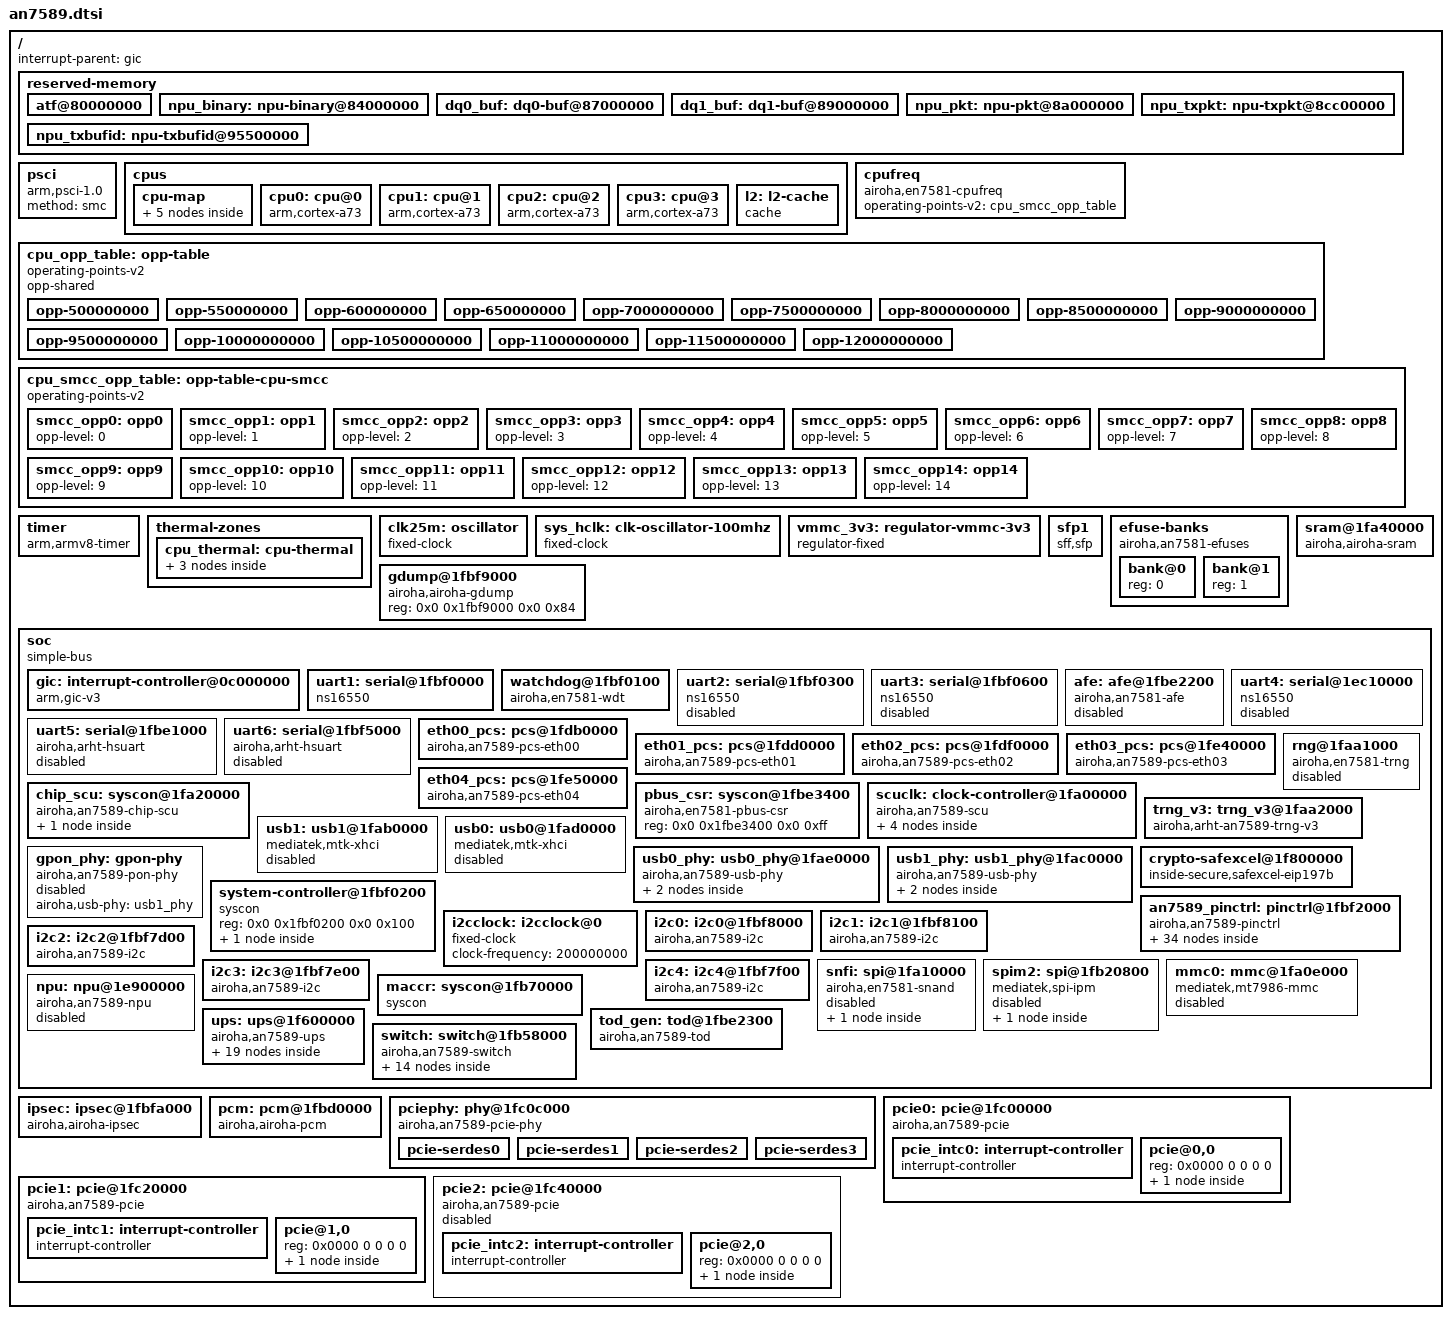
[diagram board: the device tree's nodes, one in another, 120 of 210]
// SPDX-License-Identifier: (GPL-2.0-only OR BSD-2-Clause)

#include <dt-bindings/interrupt-controller/irq.h>
#include <dt-bindings/interrupt-controller/arm-gic.h>
#include <dt-bindings/clock/en7523-clk.h>
#include <dt-bindings/phy/phy.h>
#include <dt-bindings/reset/airoha,en7581-reset.h>
#include <dt-bindings/reset/airoha,an7583-reset.h>
#include <dt-bindings/reset/airoha,an7589-reset.h>
#include <dt-bindings/phy/airoha,an7581-usb-phy.h>
#include <dt-bindings/leds/common.h>
#include <dt-bindings/thermal/thermal.h>

/ {
	interrupt-parent = <&gic>;
	#address-cells = <2>;
	#size-cells = <2>;

	reserved-memory {
		#address-cells = <2>;
		#size-cells = <2>;
		ranges;

		atf@80000000 {
			no-map;
			reg = <0x0 0x80000000 0x0 0x200000>;
		};

		npu_binary: npu-binary@84000000 {
			no-map;
			reg = <0x0 0x84000000 0x0 0xa00000>;
		};
		/*
		ai_npu_freeRTOS: ai-npu-freeRTOS@84a00000{
			no-map;
			reg = <0x0 0x84a00000 0x0 0x800000>;
		};
		ai_npu_input: ai-npu-input@85a00000 {
			no-map;
			reg = <0x0 0x85a00000 0x0 0x20000>;
		};

		ai_npu_model: ai-npu-model@86000000 {
			no-map;
			reg = <0x0 0x86000000 0x0 0x100000>;
		};

		ai_npu_mbox: ai-npu-mbox@86100000 {
			no-map;
			reg = <0x0 0x86100000 0x0 0x10000>;
		};
		*/
		dq0_buf: dq0-buf@87000000 {
			no-map;
			reg = <0x0 0x87000000 0x0 0x2000000>;
		};

		dq1_buf: dq1-buf@89000000 {
			no-map;
			reg = <0x0 0x89000000 0x0 0x1000000>;
		};

		npu_pkt: npu-pkt@8a000000 {
			no-map;
			reg = <0x0 0x8a000000 0x0 0x2c00000>;
		};

		npu_txpkt: npu-txpkt@8cc00000 {
			no-map;
			reg = <0x0 0x8cc00000 0x0 0x8900000>;
		};

		npu_txbufid: npu-txbufid@95500000  {
			no-map;
			reg = <0x0 0x95500000 0x0 0x6800>;
		};
	};

	psci {
		compatible = "arm,psci-1.0";
		method = "smc";
	};

	cpus {
		#address-cells = <1>;
		#size-cells = <0>;

		cpu-map {
			cluster0 {
				core0 {
					cpu = <&cpu0>;
				};

				core1 {
					cpu = <&cpu1>;
				};

				core2 {
					cpu = <&cpu2>;
				};

				core3 {
					cpu = <&cpu3>;
				};
			};
		};

		cpu0: cpu@0 {
			device_type = "cpu";
			compatible = "arm,cortex-a73";
			reg = <0x0>;
			operating-points-v2 = <&cpu_opp_table>;
			enable-method = "psci";
			clocks = <&cpufreq>;
			clock-names = "cpu";
			power-domains = <&cpufreq>;
			power-domain-names = "perf";
			next-level-cache = <&l2>;
			#cooling-cells = <2>;
		};

		cpu1: cpu@1 {
			device_type = "cpu";
			compatible = "arm,cortex-a73";
			reg = <0x1>;
			operating-points-v2 = <&cpu_opp_table>;
			enable-method = "psci";
			clocks = <&cpufreq>;
			clock-names = "cpu";
			power-domains = <&cpufreq>;
			power-domain-names = "perf";
			next-level-cache = <&l2>;
			#cooling-cells = <2>;
		};

		cpu2: cpu@2 {
			device_type = "cpu";
			compatible = "arm,cortex-a73";
			reg = <0x2>;
			operating-points-v2 = <&cpu_opp_table>;
			enable-method = "psci";
			clocks = <&cpufreq>;
			clock-names = "cpu";
			power-domains = <&cpufreq>;
			power-domain-names = "perf";
			next-level-cache = <&l2>;
			#cooling-cells = <2>;
		};

		cpu3: cpu@3 {
			device_type = "cpu";
			compatible = "arm,cortex-a73";
			reg = <0x3>;
			operating-points-v2 = <&cpu_opp_table>;
			enable-method = "psci";
			clocks = <&cpufreq>;
			clock-names = "cpu";
			power-domains = <&cpufreq>;
			power-domain-names = "perf";
			next-level-cache = <&l2>;
			#cooling-cells = <2>;
		};

		l2: l2-cache {
			compatible = "cache";
			cache-size = <0x80000>;
			cache-line-size = <64>;
			cache-level = <2>;
			cache-unified;
		};
	};

	cpufreq: cpufreq {
		compatible = "airoha,en7581-cpufreq";

		operating-points-v2 = <&cpu_smcc_opp_table>;

		#power-domain-cells = <0>;
		#clock-cells = <0>;
	};

	cpu_opp_table: opp-table {
		compatible = "operating-points-v2";
		opp-shared;

		opp-500000000 {
			opp-hz = /bits/ 64 <500000000>;
			required-opps = <&smcc_opp0>;
		};

		opp-550000000 {
			opp-hz = /bits/ 64 <550000000>;
			required-opps = <&smcc_opp1>;
		};

		opp-600000000 {
			opp-hz = /bits/ 64 <600000000>;
			required-opps = <&smcc_opp2>;
		};

		opp-650000000 {
			opp-hz = /bits/ 64 <650000000>;
			required-opps = <&smcc_opp3>;
		};

		opp-7000000000 {
			opp-hz = /bits/ 64 <700000000>;
			required-opps = <&smcc_opp4>;
		};

		opp-7500000000 {
			opp-hz = /bits/ 64 <750000000>;
			required-opps = <&smcc_opp5>;
		};

		opp-8000000000 {
			opp-hz = /bits/ 64 <800000000>;
			required-opps = <&smcc_opp6>;
		};

		opp-8500000000 {
			opp-hz = /bits/ 64 <850000000>;
			required-opps = <&smcc_opp7>;
		};

		opp-9000000000 {
			opp-hz = /bits/ 64 <900000000>;
			required-opps = <&smcc_opp8>;
		};

		opp-9500000000 {
			opp-hz = /bits/ 64 <950000000>;
			required-opps = <&smcc_opp9>;
		};

		opp-10000000000 {
			opp-hz = /bits/ 64 <1000000000>;
			required-opps = <&smcc_opp10>;
		};

		opp-10500000000 {
			opp-hz = /bits/ 64 <1050000000>;
			required-opps = <&smcc_opp11>;
		};

		opp-11000000000 {
			opp-hz = /bits/ 64 <1100000000>;
			required-opps = <&smcc_opp12>;
		};

		opp-11500000000 {
			opp-hz = /bits/ 64 <1150000000>;
			required-opps = <&smcc_opp13>;
		};

		opp-12000000000 {
			opp-hz = /bits/ 64 <1200000000>;
			required-opps = <&smcc_opp14>;
		};
	};

	cpu_smcc_opp_table: opp-table-cpu-smcc {
		compatible = "operating-points-v2";

		smcc_opp0: opp0 {
			opp-level = <0>;
		};

		smcc_opp1: opp1 {
			opp-level = <1>;
		};

		smcc_opp2: opp2 {
			opp-level = <2>;
		};

		smcc_opp3: opp3 {
			opp-level = <3>;
		};

		smcc_opp4: opp4 {
			opp-level = <4>;
		};

		smcc_opp5: opp5 {
			opp-level = <5>;
		};

		smcc_opp6: opp6 {
			opp-level = <6>;
		};

		smcc_opp7: opp7 {
			opp-level = <7>;
		};

		smcc_opp8: opp8 {
			opp-level = <8>;
		};

		smcc_opp9: opp9 {
			opp-level = <9>;
		};

		smcc_opp10: opp10 {
			opp-level = <10>;
		};

		smcc_opp11: opp11 {
			opp-level = <11>;
		};

		smcc_opp12: opp12 {
			opp-level = <12>;
		};

		smcc_opp13: opp13 {
			opp-level = <13>;
		};

		smcc_opp14: opp14 {
			opp-level = <14>;
		};
	};

	timer {
		compatible = "arm,armv8-timer";
		interrupt-parent = <&gic>;
		interrupts = <GIC_PPI 13 IRQ_TYPE_LEVEL_LOW>,
			     <GIC_PPI 14 IRQ_TYPE_LEVEL_LOW>,
			     <GIC_PPI 11 IRQ_TYPE_LEVEL_LOW>,
			     <GIC_PPI 10 IRQ_TYPE_LEVEL_LOW>;
	};

	thermal-zones {
		cpu_thermal: cpu-thermal {
			polling-delay-passive = <1000>;
			polling-delay = <5000>;

			thermal-sensors = <&thermal 0>;

			trips {
				cpu_hot: cpu-hot {
					temperature = <95000>;
					hysteresis = <1000>;
					type = "hot";
				};

				cpu-critical {
					temperature = <120000>;
					hysteresis = <1000>;
					type = "critical";
				};
			};
#if 0
			cooling-maps {
				map0 {
					trip = <&cpu_hot>;
					cooling-device = <&cpu0 THERMAL_NO_LIMIT THERMAL_NO_LIMIT>,
							 <&cpu1 THERMAL_NO_LIMIT THERMAL_NO_LIMIT>,
							 <&cpu2 THERMAL_NO_LIMIT THERMAL_NO_LIMIT>,
							 <&cpu3 THERMAL_NO_LIMIT THERMAL_NO_LIMIT>;
				};
			};
#endif
		};
	};

	clk25m: oscillator {
		compatible = "fixed-clock";
		#clock-cells = <0>;
		clock-frequency = <25000000>;
		clock-output-names = "clkxtal";
	};

	sys_hclk: clk-oscillator-100mhz {
		compatible = "fixed-clock";
		#clock-cells = <0>;
		clock-frequency = <100000000>;
		clock-output-names = "sys_hclk";
	};

	vmmc_3v3: regulator-vmmc-3v3 {
		compatible = "regulator-fixed";
		regulator-name = "vmmc";
		regulator-min-microvolt = <3300000>;
		regulator-max-microvolt = <3300000>;
		regulator-always-on;
	};

	sfp1: sfp1 {
		compatible = "sff,sfp";
	};

	efuse-banks {
		compatible = "airoha,an7581-efuses";
		#address-cells = <1>;
		#size-cells = <0>;

		bank@0 {
			reg = <0>;
		};

		bank@1 {
			reg = <1>;
		};
	};

	gdump@1fbf9000 {
		compatible = "airoha,airoha-gdump";
		reg = <0x0 0x1fbf9000 0x0 0x84>;
	};

	sram@1fa40000 {
		compatible = "airoha,airoha-sram";
		reg = <0x0 0x1fa40000 0x0 0x10000>,		//GDMP SRAM
			  <0x0 0x1f400000 0x0 0x10000>;		//GDMP SRAM2 (for 7589)
	};

	soc {
		compatible = "simple-bus";
		#address-cells = <2>;
		#size-cells = <2>;
		ranges;

		gic: interrupt-controller@0c000000{
			compatible = "arm,gic-v3";
			interrupt-controller;
			#interrupt-cells = <3>;
			#address-cells = <1>;
			#size-cells = <1>;
			reg = <0x0 0x0c000000 0x0 0x40000>,
				  <0x0 0x0c080000 0x0 0x200000>,
				  <0x0 0x0c400000 0x0 0x2000>,
				  <0x0 0x0c410000 0x0 0x1000>,
				  <0x0 0x0c420000 0x0 0x1000>;
			interrupts = <GIC_PPI 9 IRQ_TYPE_LEVEL_LOW>;
		};

		uart1: serial@1fbf0000 {
			compatible = "ns16550";
			reg = <0x0 0x1fbf0000 0x0 0x30>;
			reg-io-width = <4>;
			reg-shift = <2>;
			interrupts = <GIC_SPI 74 IRQ_TYPE_LEVEL_HIGH>;
			clock-frequency = <1843200>;
		};

		watchdog@1fbf0100 {
			compatible = "airoha,en7581-wdt";
			reg = <0x0 0x1fbf0100 0x0 0x38>;

			clocks = <&sys_hclk>;
			clock-names = "bus";
		};

		uart2: serial@1fbf0300 {
			compatible = "ns16550";
			reg = <0x0 0x1fbf0300 0x0 0x30>;
			reg-io-width = <4>;
			reg-shift = <2>;
			interrupts = <GIC_SPI 88 IRQ_TYPE_LEVEL_HIGH>;
			clock-frequency = <1843200>;

			status = "disabled";
		};

		uart3: serial@1fbf0600 {
			compatible = "ns16550";
			reg = <0x0 0x1fbf0600 0x0 0x30>;
			reg-io-width = <4>;
			reg-shift = <2>;
			interrupts = <GIC_SPI 110 IRQ_TYPE_LEVEL_HIGH>;
			clock-frequency = <1843200>;

			status = "disabled";
		};

		afe: afe@1fbe2200 {
			compatible = "airoha,an7581-afe";
			reg = <0x0 0x1fbe2200 0x0 0xfc>,
				<0x0 0x1fbe2f00 0x0 0x14>;
			interrupts = <GIC_SPI 104 IRQ_TYPE_LEVEL_HIGH>;

			resets = <&scuclk AN7589_I2S_RST>;

			status = "disabled";
		};

		uart4: serial@1ec10000 {
			compatible = "ns16550";
			reg = <0x0 0x1ec10000 0x0 0x30>;
			reg-io-width = <4>;
			reg-shift = <2>;
			interrupts = <GIC_SPI 160 IRQ_TYPE_LEVEL_HIGH>;
			clock-frequency = <1843200>;

			status = "disabled";
		};

		uart5: serial@1fbe1000 {
			compatible = "airoha,arht-hsuart";
			reg = <0x0 0x1fbe1000 0x0 0x80>;
			reg-io-width = <4>;
			reg-shift = <2>;
			interrupts = <GIC_SPI 117 IRQ_TYPE_LEVEL_HIGH>;
			clock-frequency = <14745600>;
			port-index = <0>;

			status = "disabled";
		};

		uart6: serial@1fbf5000 {
			compatible = "airoha,arht-hsuart";
			reg = <0x0 0x1fbf5000 0x0 0x80>;
			reg-io-width = <4>;
			reg-shift = <2>;
			interrupts = <GIC_SPI 118 IRQ_TYPE_LEVEL_HIGH>;
			clock-frequency = <14745600>;
			port-index = <1>;

			status = "disabled";
		};

		eth00_pcs: pcs@1fdb0000 {
			compatible = "airoha,an7589-pcs-eth00";
			reg = <0x0 0x1fdb0000 0x0 0x64>,
				  <0x0 0x1fdb1000 0x0 0x64>,
				  <0x0 0x1fdb2000 0x0 0x64>,
				  <0x0 0x1fdb3000 0x0 0x64>,
			      <0x0 0x1fdb0a00 0x0 0x1b0>,
			      <0x0 0x1fdb8000 0x0 0x58c>,
			      <0x0 0x1fdb0c00 0x0 0x3a8>,
			      <0x0 0x1fdb9000 0x0 0x748>,
				  <0x0 0x1fdb1c00 0x0 0x400>,
				  <0x0 0x1fdb2c00 0x0 0x400>,
				  <0x0 0x1fdbc000 0x0 0x250>,
				  <0x0 0x1fda0000 0x0 0x9000>;
			reg-names = "hsgmii_an", "hsgmii_an_p1", "hsgmii_an_p2",
					"hsgmii_an_p3","hsgmii_pcs", "multi_sgmii", "usxgmii",
					"hsgmii_rate_adp", "usxgmii_m_1", "usxgmii_m_2", "qsgmii", "pma";

			// resets = <&scuclk AN7583_XSI_MAC_RST>,
			//	 <&scuclk AN7583_XSI_PHY_RST>;
			// reset-names = "mac", "phy";

			airoha,scu = <&scuclk>;
		};

		eth01_pcs: pcs@1fdd0000 {
			compatible = "airoha,an7589-pcs-eth01";
			reg = <0x0 0x1fdd0000 0x0 0x64>,
				  <0x0 0x1fdd1000 0x0 0x64>,
				  <0x0 0x1fdd2000 0x0 0x64>,
				  <0x0 0x1fdd3000 0x0 0x64>,
			      <0x0 0x1fdd0a00 0x0 0x1b0>,
			      <0x0 0x1fdd8000 0x0 0x58c>,
			      <0x0 0x1fdd0c00 0x0 0x3a8>,
			      <0x0 0x1fdd9000 0x0 0x748>,
				  <0x0 0x1fdd1c00 0x0 0x400>,
				  <0x0 0x1fdd2c00 0x0 0x400>,
				  <0x0 0x1fddc000 0x0 0x250>,
				  <0x0 0x1fdc0000 0x0 0x9000>;
			reg-names = "hsgmii_an", "hsgmii_an_p1","hsgmii_an_p2",
					"hsgmii_an_p3","hsgmii_pcs", "multi_sgmii", "usxgmii",
					"hsgmii_rate_adp", "usxgmii_m_1", "usxgmii_m_2",  "qsgmii", "pma";

			// resets = <&scuclk AN7583_XSI_MAC_RST>,
			//	 <&scuclk AN7583_XSI_PHY_RST>;
			// reset-names = "mac", "phy";

			airoha,scu = <&scuclk>;
		};

		eth02_pcs: pcs@1fdf0000 {
			compatible = "airoha,an7589-pcs-eth02";
			reg = <0x0 0x1fdf0000 0x0 0x414>,
				  <0x0 0x1fdf1000 0x0 0x404>,
				  <0x0 0x1fdf2000 0x0 0x764>,
				  <0x0 0x1fdf3000 0x0 0x23c>,
				  <0x0 0x1fdf4000 0x0 0xc0c>,
				  <0x0 0x1fdf5000 0x0 0x424>,
				  <0x0 0x1fdf6000 0x0 0x90c>,
				  <0x0 0x1fdf7000 0x0 0xc20>,
				  <0x0 0x1fdf8000 0x0 0x314>,
				  <0x0 0x1fdf9000 0x0 0xd8>,
				  <0x0 0x1fde0000 0x0 0x9000>;
			reg-names = "ethl_0", "ethl_1", "ethl_misc",
				    "ethl_com", "ethl_txm", "ethl_rxm", "ethl_txl",
				    "ethl_rxl", "ethl_fifo", "ethl_ra", "pma";

			// resets = <&scuclk AN7583_XSI_MAC_RST>,
			//	 <&scuclk AN7583_XSI_PHY_RST>;
			// reset-names = "mac", "phy";

			airoha,scu = <&scuclk>;
		};

		eth03_pcs: pcs@1fe40000 {
			compatible = "airoha,an7589-pcs-eth03";
			reg = <0x0 0x1fe40000 0x0 0x414>,
				  <0x0 0x1fe41000 0x0 0x404>,
				  <0x0 0x1fe42000 0x0 0x764>,
				  <0x0 0x1fe43000 0x0 0x23c>,
				  <0x0 0x1fe44000 0x0 0xc0c>,
				  <0x0 0x1fe45000 0x0 0x424>,
				  <0x0 0x1fe46000 0x0 0x90c>,
				  <0x0 0x1fe47000 0x0 0xc20>,
				  <0x0 0x1fe48000 0x0 0x314>,
				  <0x0 0x1fe49000 0x0 0xd8>,
				  <0x0 0x1fe30000 0x0 0xf000>;
			reg-names = "ethl_0", "ethl_1", "ethl_misc",
				    "ethl_com", "ethl_txm", "ethl_rxm", "ethl_txl",
				    "ethl_rxl", "ethl_fifo", "ethl_ra", "pma";

			// resets = <&scuclk AN7583_XSI_MAC_RST>,
			// 	 <&scuclk AN7583_XSI_PHY_RST>;
			// reset-names = "mac", "phy";

			airoha,scu = <&scuclk>;
		};

		eth04_pcs: pcs@1fe50000 {
			compatible = "airoha,an7589-pcs-eth04";
			reg = <0x0 0x1fe50000 0x0 0x414>,
				  <0x0 0x1fe51000 0x0 0x404>,
				  <0x0 0x1fe52000 0x0 0x764>,
				  <0x0 0x1fe53000 0x0 0x23c>,
				  <0x0 0x1fe54000 0x0 0xc0c>,
				  <0x0 0x1fe55000 0x0 0x424>,
				  <0x0 0x1fe56000 0x0 0x90c>,
				  <0x0 0x1fe57000 0x0 0xc20>,
				  <0x0 0x1fe58000 0x0 0x314>,
				  <0x0 0x1fe59000 0x0 0xd8>,
				  <0x0 0x1feb0000 0x0 0xf000>;
			reg-names = "ethl_0", "ethl_1", "ethl_misc",
				    "ethl_com", "ethl_txm", "ethl_rxm", "ethl_txl",
				    "ethl_rxl", "ethl_fifo", "ethl_ra", "pma";

			resets = <&scuclk AN7583_XSI_MAC_RST>,
				 <&scuclk AN7583_XSI_PHY_RST>;
			reset-names = "mac", "phy";

			airoha,scu = <&scuclk>;
		};

		chip_scu: syscon@1fa20000 {
			compatible = "airoha,an7589-chip-scu", "simple-mfd", "syscon";
			reg = <0x0 0x1fa20000 0x0 0x410>;
			interrupts = <GIC_SPI 103 IRQ_TYPE_LEVEL_HIGH>;
			thermal: thermal-sensor {
				compatible = "airoha,an7589-thermal";
				#thermal-sensor-cells = <0>;
			};
		};

		pbus_csr: syscon@1fbe3400 {
			compatible = "airoha,en7581-pbus-csr", "syscon";
			reg = <0x0 0x1fbe3400 0x0 0xff>;
		};

		scuclk: clock-controller@1fa00000 {
			compatible = "airoha,an7589-scu", "syscon";
			reg = <0x0 0x1fb00000 0x0 0x9fc>;

			#address-cells = <1>;
			#size-cells = <0>;

			#clock-cells = <1>;
			#reset-cells = <1>;

			airoha,chip-scu = <&chip_scu>;

			mdio_0: mdio-bus@c8 {
				compatible = "airoha,an7583-mdio";
				reg = <0xc8>;

				clocks = <&scuclk AN7583_CLK_MDIO0>;
				resets = <&scuclk AN7589_MDIO0>;
			};

			mdio_1: mdio-bus@cc {
				compatible = "airoha,an7583-mdio";
				reg = <0xcc>;

				clocks = <&scuclk AN7583_CLK_MDIO1>;
				resets = <&scuclk AN7589_MDIO1>;
			};

			mdio_2: mdio-bus@d8 {
				compatible = "airoha,an7583-mdio";
				reg = <0xd8>;

				clocks = <&scuclk AN7589_CLK_MDIO2>;
				resets = <&scuclk AN7589_MDIO2>;
			};

			scu_ssr: system-controller {
				compatible = "airoha,an7581-scu-ssr";
			};
		};
		rng@1faa1000 {
			compatible = "airoha,en7581-trng";
			reg = <0x0 0x1faa1000 0x0 0xc04>;
			interrupts = <GIC_SPI 91 IRQ_TYPE_LEVEL_HIGH>;
			status = "disabled";
		};

		trng_v3: trng_v3@1faa2000 {
			compatible = "airoha,arht-an7589-trng-v3";
			reg = <0x0 0x1faa2000 0x0 0x300>;
			interrupts = <GIC_SPI 203 IRQ_TYPE_LEVEL_HIGH>;
			status = "okay";
		};

		usb1: usb1@1fab0000 {
			compatible = "mediatek,mtk-xhci";
			reg = <0x0 0x1fab0000 0x0 0x3e00>,
				<0x0 0x1fab3e00 0x0 0x100>;
			reg-names = "mac", "ippc";
			interrupts = <GIC_SPI 89 IRQ_TYPE_LEVEL_HIGH>;
			phys = <&usb1_u2 PHY_TYPE_USB2>, <&usb1_u3 PHY_TYPE_USB3>;
			status = "disabled";
		};

		usb0: usb0@1fad0000 {
			compatible = "mediatek,mtk-xhci";
			reg = <0x0 0x1fad0000 0x0 0x3e00>,
				<0x0 0x1fad3e00 0x0 0x100>;
			reg-names = "mac", "ippc";
			interrupts = <GIC_SPI 206 IRQ_TYPE_LEVEL_HIGH>;
			phys = <&usb0_u2 PHY_TYPE_USB2>, <&usb0_u3 PHY_TYPE_USB3>;
			status = "disabled";
		};

		usb0_phy: usb0_phy@1fae0000 {
			compatible = "airoha,an7589-usb-phy";
			reg = <0x0 0x1fae0000 0x0 0x11ff>,
			      <0x0 0x1fedf000 0x0 0xff>,
			      <0x0 0x1fed0000 0x0 0x8ff>,
			      <0x0 0x1feda000 0x0 0x3ff>,
			      <0x0 0x1fbe2100 0x0 0xff>;
			reg-names = "phy", "ana", "pma", "dig", "csr";


			airoha,port-id = <0>;
			airoha,scu-ssr = <&scu_ssr>;

			usb0_u2: usb2-phy {
				reg = <0x0>;
				airoha,usb2-monitor-clk-sel = <AIROHA_USB2_MONCLK_SEL1>;

				#phy-cells = <1>;
			};

			usb0_u3: usb3-phy {
				airoha,scu = <&scuclk>;

				#phy-cells = <1>;
			};
		};

		usb1_phy: usb1_phy@1fac0000 {
			compatible = "airoha,an7589-usb-phy";
			reg = <0x0 0x1fac0000 0x0 0x11ff>,
			      <0x0 0x1fe7f000 0x0 0xff>,
			      <0x0 0x1fe70000 0x0 0x8ff>,
			      <0x0 0x1fe7a000 0x0 0x3ff>,
			      <0x0 0x1fbe2000 0x0 0xff>;
			reg-names = "phy", "ana", "pma", "dig", "csr";


			airoha,port-id = <1>;
			airoha,scu-ssr = <&scu_ssr>;

			usb1_u2: usb2-phy {
				reg = <0x0>;
				airoha,usb2-monitor-clk-sel = <AIROHA_USB2_MONCLK_SEL2>;

				#phy-cells = <1>;
			};

			usb1_u3: usb3-phy {
				airoha,scu = <&scuclk>;

				#phy-cells = <1>;
			};
		};

		gpon_phy: gpon-phy {
			compatible = "airoha,an7589-pon-phy";
			airoha,usb-phy = <&usb1_phy>;
			status = "disabled";
		};

		crypto-safexcel@1f800000 {
			compatible = "inside-secure,safexcel-eip197b",
					"security-ip-197_srv";
			reg = <0x0 0x1f800000 0x0 0x200000>,
				<0x0 0x1f630000 0x0 0x8000>;
			interrupts = <GIC_SPI 135 IRQ_TYPE_LEVEL_HIGH>, //63+72
					<GIC_SPI 75 IRQ_TYPE_LEVEL_HIGH>, //3+72
					<GIC_SPI 209 IRQ_TYPE_LEVEL_HIGH>, //137+72
					<GIC_SPI 267 IRQ_TYPE_LEVEL_HIGH>, //195+72
					<GIC_SPI 274 IRQ_TYPE_LEVEL_HIGH>; //202+72
			interrupt-names = "global","ring0","ring1","ring2","ring3";
			status = "okay";
		};

		system-controller@1fbf0200 {
			compatible = "syscon", "simple-mfd";
			reg = <0x0 0x1fbf0200 0x0 0x100>;
#if 0
			en7581_pinctrl: pinctrl {
				compatible = "airoha,en7581-pinctrl";

				interrupt-parent = <&gic>;
				interrupts = <GIC_SPI 26 IRQ_TYPE_LEVEL_HIGH>;

				gpio-controller;
				#gpio-cells = <2>;

				interrupt-controller;
				#interrupt-cells = <2>;
			};
#endif
			an7589_pwm: pwm {
				compatible = "airoha,an7589-pwm";

				#pwm-cells = <3>;
			};
		};


		/*
		 * GPIO and Pinctrl Controller
		 *
		 * AN7589 uses two separate register regions:
		 * 1. GPIO control base @ 0x1FBF2000 - DIR, DOUT, DIN, INT, PULL, DRV
		 *    (Source: AN7589_GPIO_CODA_GPIO_internal.docx)
		 * 2. IOMUX base @ 0x1FA30000 - MODE registers for pin multiplexing
		 *    (Source: acd2coda_default_gpio_reg_internal.docx)
		 */
		an7589_pinctrl: pinctrl@1fbf2000 {
			compatible = "airoha,an7589-pinctrl";

			/* Two register regions */
			reg = <0x0 0x1fbf0200 0x0 0x100>,  /* GPIO control base */
			      <0x0 0x1fa30000 0x0 0x34>;  /* IOMUX base */
			reg-names = "base", "iomux";

			gpio-controller;
			#gpio-cells = <2>;

			interrupt-controller;
			#interrupt-cells = <2>;
			interrupts = <GIC_SPI 82 IRQ_TYPE_LEVEL_HIGH>;

			i2c0_pins: i2c0-pins {
				mux {
					function = "i2c0";
					groups = "i2c0_grp";
				};
			};

			i2c3_pins: i2c3-pins {
				mux {
					function = "i2c3";
					groups = "i2c3_grp";
				};
			};

			mmc_pins: mmc-pins {
				mux {
					function = "emmc";
					groups = "emmc_grp";
				};
			};

			uart2_pins: uart2-pins {
				mux {
					function = "uart2";
					groups = "uart2_grp";
				};
			};

			uart3_pins: uart3-pins {
				mux {
					function = "uart3";
					groups = "uart3_grp";
				};
			};

			uart4_pins: uart4-pins {
				mux {
					function = "uart4";
					groups = "uart4_grp";
				};
			};

			uart5_pins: uart5-pins {
				mux {
					function = "uart5";
					groups = "uart5_grp";
				};
			};

			uart6_pins: uart6-pins {
				mux {
					function = "uart6";
					groups = "uart6_grp";
				};
			};

			i2s_pins: i2s-pins {
				mux {
					function = "i2s";
					groups = "i2s_grp";
				};
			};

			pcm1_pins: pcm1-pins {
				mux {
					function = "pcm1";
					groups = "pcm1_grp";
				};
			};

			pon1_default_pins: pon1_default_pins {
				mux {
					function = "pon1";
					groups = "pon1_default_grp";
				};
			};

			pon1_working_pins: pon1_working_pins {
				mux {
					function = "pon1";
					groups = "pon1_working_grp";
				};
			};

			pon1_reset_pins: pon1_reset_pins {
				mux {
					function = "pon1";
					groups = "pon1_reset_grp";
				};
			};

			pon2_default_pins: pon2_default_pins {
				mux {
					function = "pon2";
					groups = "pon2_default_grp";
				};
			};

			pon2_working_pins: pon2_working_pins {
				mux {
					function = "pon2";
					groups = "pon2_working_grp";
				};
			};

			pon2_reset_pins: pon2_reset_pins {
				mux {
					function = "pon2";
					groups = "pon2_reset_grp";
				};
			};

			ext_spi2_full_pins: ext-spi2-full-pins {
				mux {
					function = "ext_spi2";
					groups = "ext_spi2_full_grp";
				};
			};
		};

#if 0
		spi_ctrl: spi_controller@1fa10000 {
			compatible = "econet,ecnt-spi_ctrl";
			reg = <0x0 0x1fa10000 0x0 0x140>,		//SPI Controller Base
				  <0x0 0x00000000 0x0 0x1000>;		//SPI Controller auto read interrupt test
			interrupts = <GIC_SPI 51 IRQ_TYPE_LEVEL_HIGH>;
		};

		spi_spi2nfi: spi_spi2nfi@1fa11000 {
			compatible = "econet,ecnt-spi2nfi";
			reg = <0x0 0x1fa11000 0x0 0x160>;	//NFI2SPI
		};

		spi_ecc: spi_ecc@1fa12000 {
			compatible = "econet,ecnt-spi_ecc";
			reg = <0x0 0x1fa12000 0x0 0x150>;	//NFI ECC
		};

		nand_flash: nand@1fa10000 {
			compatible = "econet,ecnt-nand";
			spi-controller = <&spi_ctrl>;
			spi2nfi = <&spi_spi2nfi>;
			spi-ecc = <&spi_ecc>;
		};
#endif
		i2cclock: i2cclock@0 {
			#clock-cells = <0>;
			compatible = "fixed-clock";

			/* 160 MHz for FPGA, 200 MHz for ASIC*/
			clock-frequency = <200000000>;
		};

		i2c0: i2c0@1fbf8000 {
			compatible = "airoha,an7589-i2c";
			reg = <0x0 0x1fbf8000 0x0 0x100>;

			clocks = <&i2cclock>;

			/* 100 kHz */
			clock-frequency = <100000>;
			#address-cells = <1>;
			#size-cells = <0>;

			status = "okay";
		};

		i2c1: i2c1@1fbf8100 {
			compatible = "airoha,an7589-i2c";
			reg = <0x0 0x1fbf8100 0x0 0x100>;

			clocks = <&i2cclock>;

			/* 100 kHz */
			clock-frequency = <100000>;
			#address-cells = <1>;
			#size-cells = <0>;

			status = "okay";
		};

		i2c2: i2c2@1fbf7d00 {
			compatible = "airoha,an7589-i2c";
			reg = <0x0 0x1fbf7d00 0x0 0x100>;

			clocks = <&i2cclock>;

			/* 100 kHz */
			clock-frequency = <100000>;
			#address-cells = <1>;
			#size-cells = <0>;

			status = "okay";
		};

		i2c3: i2c3@1fbf7e00 {
			compatible = "airoha,an7589-i2c";
			reg = <0x0 0x1fbf7e00 0x0 0x100>;

			clocks = <&i2cclock>;

			/* 100 kHz */
			clock-frequency = <100000>;
			#address-cells = <1>;
			#size-cells = <0>;

			status = "okay";
		};

		i2c4: i2c4@1fbf7f00 {
			compatible = "airoha,an7589-i2c";
			reg = <0x0 0x1fbf7f00 0x0 0x100>;

			clocks = <&i2cclock>;

			/* 100 kHz */
			clock-frequency = <100000>;
			#address-cells = <1>;
			#size-cells = <0>;

			status = "okay";
		};

		snfi: spi@1fa10000 {
			compatible = "airoha,en7581-snand";
			reg = <0x0 0x1fa10000 0x0 0x140>,
			      <0x0 0x1fa11000 0x0 0x600>;

			clocks = <&scuclk EN7523_CLK_SPI>;
			clock-names = "spi";

			#address-cells = <1>;
			#size-cells = <0>;

			status = "disabled";

			spi_nand: nand@0 {
				compatible = "spi-nand";
				reg = <0>;
				spi-max-frequency = <50000000>;
				spi-tx-bus-width = <1>;
				spi-rx-bus-width = <2>;
			};
		};

		/* Non-boot SPI-NOR connected to SPIM2 (GPIO27/28/30-33). */
		spim2: spi@1fb20800 {
			compatible = "mediatek,spi-ipm";
			reg = <0 0x1fb20800 0 0x1000>;
			interrupts = <GIC_SPI 203 IRQ_TYPE_LEVEL_HIGH>;
			pinctrl-names = "default";
			pinctrl-0 = <&ext_spi2_full_pins>;
			mediatek,pad-select = <0>;
			clocks = <&scuclk CLK_TOP_CB_M_D2>,
				 <&scuclk CLK_TOP_SPI2_SEL>,
				 <&scuclk CLK_INFRA_104M_SPI2>,
				 <&scuclk CLK_INFRA_66M_SPI2_HCK>;
			clock-names = "parent-clk", "sel-clk", "spi-clk", "hclk";
			/* Select the 200 MHz SPIM2 source; IPM divides it to 50 MHz. */
			assigned-clocks = <&scuclk CLK_INFRA_104M_SPI2>;
			assigned-clock-rates = <200000000>;
			#address-cells = <1>;
			#size-cells = <0>;
			status = "disabled";

			spim2_nor: flash@0 {
				compatible = "jedec,spi-nor";
				reg = <0>;
				spi-max-frequency = <50000000>;
				/* AN7589 IPM input sampling delay for the external NOR. */
				mediatek,tick-delay = <3>;
				/* Validate Dual I/O at the established 50 MHz clock rate. */
				spi-tx-bus-width = <2>;
				spi-rx-bus-width = <2>;

				/*
				 * TODO: Quad I/O requires board support for NOR IO2/IO3.
				 * Do not enable it on the current hardware.
				 * spi-tx-bus-width = <4>;
				 * spi-rx-bus-width = <4>;
				 */
			};
		};

		mmc0: mmc@1fa0e000 {
			compatible = "mediatek,mt7986-mmc";
			reg = <0x0 0x1fa0e000 0x0 0x1000>,
			      <0x0 0x1fa0c000 0x0 0x60>;
			interrupts = <GIC_SPI 226 IRQ_TYPE_LEVEL_HIGH>;	// 226 = 154 + 72
			clocks = <&scuclk EN7581_CLK_EMMC>, <&clk25m>;
			clock-names = "source", "hclk";
			bus-width = <8>;
			max-frequency = <200000000>;
			vmmc-supply = <&vmmc_3v3>;
			disable-wp;
			cap-mmc-highspeed;
			mmc-hs200-1_8v;
			mmc-hs400-1_8v;
			mmc-hs400-enhanced-strobe;
			hs400-ds-delay = <0x14014>;
			non-removable;
			no-sd;
			no-sdio;

			status = "disabled";
		};

		npu: npu@1e900000 {
			compatible = "airoha,an7589-npu";
			reg = <0x0 0x1e900000 0x0 0x317000>, //NEQ reg 0x1ec1_6800 - 0x1ec1_6FFF
				<0x0 0x1e800000 0x0 0x60000>,
				<0x0 0x70200000 0x0 0x88000>,
				<0x0 0x70300000 0x0 0x48000>;
			reg-names = "npuRegs", "shared_SRAM", "cluster0_SPAD", "cluster1_SPAD";
			interrupts = <GIC_SPI 181 IRQ_TYPE_LEVEL_HIGH>, 	//mbox2host irq
				<GIC_SPI 190 IRQ_TYPE_LEVEL_HIGH>,	//npu timer0 wdog intr
				<GIC_SPI 191 IRQ_TYPE_LEVEL_HIGH>,	//npu timer1 wdog intr
				<GIC_SPI 192 IRQ_TYPE_LEVEL_HIGH>,	//npu timer2 wdog intr
				<GIC_SPI 193 IRQ_TYPE_LEVEL_HIGH>,	//npu timer3 wdog intr
				<GIC_SPI 165 IRQ_TYPE_LEVEL_HIGH>,	//npu timer4 wdog intr
				<GIC_SPI 166 IRQ_TYPE_LEVEL_HIGH>,	//npu timer5 wdog intr
				<GIC_SPI 167 IRQ_TYPE_LEVEL_HIGH>,	//npu timer6 wdog intr
				<GIC_SPI 168 IRQ_TYPE_LEVEL_HIGH>,	//npu timer7 wdog intr
				<GIC_SPI 174 IRQ_TYPE_LEVEL_HIGH>,
				<GIC_SPI 175 IRQ_TYPE_LEVEL_HIGH>,
				<GIC_SPI 176 IRQ_TYPE_LEVEL_HIGH>,
				<GIC_SPI 177 IRQ_TYPE_LEVEL_HIGH>,
				<GIC_SPI 178 IRQ_TYPE_LEVEL_HIGH>,
				<GIC_SPI 179 IRQ_TYPE_LEVEL_HIGH>;
			memory-region = <&npu_binary>, <&npu_pkt>, <&npu_txpkt>,
					<&npu_txbufid>;
			memory-region-names = "binary", "pkt", "tx-pkt",
					      "tx-bufid";
			status = "disabled";
		};

		maccr: syscon@1fb70000 {
			compatible = "syscon";
			reg = <0 0x1fb70000 0 0x4700>,
			<0 0x1fb80000 0 0x4700>,
			<0 0x1fb90000 0 0x4100>,
			<0 0x1fba0000 0 0x4100>,
			<0 0x1fbb0000 0 0x4100>;
		};

		tod_gen: tod@1fbe2300 {
			compatible = "airoha,an7589-tod";
			reg = <0x0 0x1fbe2300 0x0 0xD0>;
			interrupts = <GIC_SPI 134 IRQ_TYPE_LEVEL_HIGH>; // TOD GEN INT 62+72
		};

		ups: ups@1f600000 {
			compatible = "airoha,an7589-ups";
			reg = <0x0 0x1f600000 0x0 0x10000>,	//DQ
				  <0x0 0x1f610000 0x0 0x4000>,	//PP
				  <0x0 0x1f614000 0x0 0x1000>,	//PDMA0
				  <0x0 0x1f615000 0x0 0x1000>,	//PDMA1
				  <0x0 0x1f616000 0x0 0x200>,	//PM
				  <0x0 0x1f616200 0x0 0x200>,	//TCE
				  <0x0 0x1f620000 0x0 0x20000>,	//TM
				  <0x0 0x1fa2ff38 0x0 0x4>;		//FPGA_STATUS
			reg-names = "dq","pp","pdma0","pdma1","pm","tce","tm","status";
			reset-names = "pdma0";
			interrupts = <GIC_SPI 93 IRQ_TYPE_LEVEL_HIGH>, // PDMA0 INT1 21+72
						   <GIC_SPI 111 IRQ_TYPE_LEVEL_HIGH>, // PDMA0 INT2 39+72
						   <GIC_SPI 112 IRQ_TYPE_LEVEL_HIGH>, // PDMA0 INT3 40+72
						   <GIC_SPI 113 IRQ_TYPE_LEVEL_HIGH>, // PDMA0 INT4 41+72
						   <GIC_SPI 301 IRQ_TYPE_LEVEL_HIGH>, // serdes00 ptp INT 229+72
						   <GIC_SPI 306 IRQ_TYPE_LEVEL_HIGH>, // serdes01 ptp INT 234+72
						   <GIC_SPI 311 IRQ_TYPE_LEVEL_HIGH>, // serdes02 ptp INT 239+72
						   <GIC_SPI 293 IRQ_TYPE_LEVEL_HIGH>, // serdes03 ptp INT 221+72
						   <GIC_SPI 282 IRQ_TYPE_LEVEL_HIGH>; // serdes04 ptp INT 210+72
			airoha,maccr = <&maccr>;
			memory-region = <&dq0_buf>, <&dq1_buf>;
			memory-region-names = "dq0_buf", "dq1_buf";

			port0: ethernet@0 {
				compatible = "airoha,eth-mac";
				reg = <0>;
				phy-mode = "internal";
				status = "okay";
				pcs = <&eth00_pcs>;

				fixed-link {
					speed = <10000>;
					full-duplex;
					pause;
				};
			};

			port1: ethernet@1 {
				compatible = "airoha,eth-mac";
				reg = <1>;
				phy-mode = "usxgmii";
				status = "okay";
				pcs = <&eth01_pcs>;


			};

			port2: ethernet@2 {
				compatible = "airoha,eth-mac";
				reg = <2>;
				phy-mode = "usxgmii";
				status = "okay";
				pcs = <&eth02_pcs>;


			};

			port3: ethernet@3 {
				compatible = "airoha,eth-mac";
				reg = <3>;
				phy-mode = "usxgmii";
				status = "okay";
				pcs = <&eth03_pcs>;

			};

			port4: ethernet@4 {
				compatible = "airoha,eth-mac";
				reg = <4>;
				phy-mode = "usxgmii";
				status = "okay";
				pcs = <&eth04_pcs>;


			};

			/* reg is keep with switch@1fb58000 subnode ports.*/
			/* type: 0(unknow), 1(cpu), 2(phy), 3(xsi). */
			eth_ports {
				xsi_port0: port@0 {
					label = "serdes_00";
					reg = <0>;
					type = <3>;
					serdes = <0>;
					index = <0>;
					dma_src_port = <0x0>;
					status = "disabled";
				};
				xsi_port1: port@1 {
					label = "serdes_00";
					reg = <1>;
					type = <3>;
					serdes = <0>;
					index = <0>;
					dma_src_port = <0x1>;
					status = "disabled";
				};
				xsi_port2: port@2 {
					label = "serdes_00";
					reg = <2>;
					type = <3>;
					serdes = <0>;
					index = <0>;
					dma_src_port = <0x2>;
					status = "disabled";
				};
				xsi_port3: port@3 {
					label = "serdes_00";
					reg = <3>;
					type = <3>;
					serdes = <0>;
					index = <0>;
					dma_src_port = <0x3>;
					status = "disabled";
				};
				xsi_port4: port@4 {
					label = "serdes_01";
					reg = <4>;
					type = <3>;
					serdes = <1>;
					index = <0>;
					dma_src_port = <0x4>;
					status = "disabled";
				};
				xsi_port5: port@5 {
					label = "serdes_01";
					reg = <5>;
					type = <3>;
					serdes = <1>;
					index = <0>;
					dma_src_port = <0x5>;
					status = "disabled";
				};
				xsi_port6: port@6 {
					label = "serdes_01";
					reg = <6>;
					type = <3>;
					serdes = <1>;
					index = <0>;
					dma_src_port = <0x6>;
					status = "disabled";
				};
				xsi_port7: port@7 {
					label = "serdes_01";
					reg = <7>;
					type = <3>;
					serdes = <1>;
					index = <0>;
					dma_src_port = <0x7>;
					status = "disabled";
				};
				xsi_port8: port@8 {
					label = "serdes_02";
					reg = <8>;
					type = <3>;
					serdes = <1>;
					index = <0>;
					dma_src_port = <0x8>;
					status = "disabled";
				};
				xsi_port9: port@9 {
					label = "serdes_03";
					reg = <9>;
					type = <3>;
					serdes = <1>;
					index = <0>;
					dma_src_port = <0x9>;
					status = "disabled";
				};
				xsi_port10: port@10 {
					label = "serdes_04";
					reg = <10>;
					type = <3>;
					serdes = <1>;
					index = <0>;
					dma_src_port = <0xa>;
					status = "disabled";
				};

				cpu_port: port@12 {
					reg = <12>;
					type = <1>;
					index = <0>;
					dma_src_port = <0xc>;
				};


			};
		};
		switch: switch@1fb58000 {
			compatible = "airoha,an7589-switch";
			airoha,maccr = <&maccr>;
			resets = <&scuclk EN7581_GSW_RST>;

			interrupt-controller;
			#interrupt-cells = <1>;
			interrupt-parent = <&gic>;
			interrupts = <GIC_SPI 265 IRQ_TYPE_LEVEL_HIGH>;

			status = "okay";

			#address-cells = <1>;
			#size-cells = <1>;

			ports {
				#address-cells = <1>;
				#size-cells = <0>;

				an7589_port1: port@0 {
					reg = <0>;
					label = "lan1";
					phy-mode = "10g-qxgmii";
					sfp = <&sfp1>;
					port-handle = <&xsi_port0>;
					managed = "in-band-status";
					status = "disabled";
				};
				an7589_port2: port@1 {
					reg = <1>;
					label = "lan2";
					phy-mode = "10g-qxgmii";
					port-handle = <&xsi_port1>;
					managed = "in-band-status";
					status = "disabled";
				};
				an7589_port3: port@2 {
					reg = <2>;
					label = "lan3";
					phy-mode = "10g-qxgmii";
					port-handle = <&xsi_port2>;
					managed = "in-band-status";
					status = "disabled";
				};
				an7589_port4: port@3 {
					reg = <3>;
					label = "lan4";
					phy-mode = "10g-qxgmii";
					port-handle = <&xsi_port3>;
					managed = "in-band-status";
					status = "disabled";
				};
				an7589_port5: port@4 {
					reg = <4>;
					label = "lan5";
					phy-mode = "usxgmii";
					sfp = <&sfp1>;
					port-handle = <&xsi_port4>;
					managed = "in-band-status";
					status = "disabled";
				};
				an7589_port6: port@5 {
					reg = <5>;
					label = "lan6";
					phy-mode = "10g-qxgmii";
					port-handle = <&xsi_port5>;
					managed = "in-band-status";
					status = "disabled";
				};
				an7589_port7: port@6 {
					reg = <6>;
					label = "lan7";
					phy-mode = "10g-qxgmii";
					port-handle = <&xsi_port6>;
					managed = "in-band-status";
					status = "disabled";
				};
				an7589_port8: port@7 {
					reg = <7>;
					label = "lan8";
					phy-mode = "10g-qxgmii";
					port-handle = <&xsi_port7>;
					managed = "in-band-status";
					status = "disabled";
				};
				an7589_port9: port@8 {
					reg = <8>;
					label = "lan9";
					phy-mode = "usxgmii";
					sfp = <&sfp1>;
					port-handle = <&xsi_port8>;
					managed = "in-band-status";
					status = "disabled";
				};
				an7589_port10: port@9 {
					reg = <9>;
					label = "lan10";
					phy-mode = "usxgmii";
					sfp = <&sfp1>;
					port-handle = <&xsi_port9>;
					managed = "in-band-status";
					status = "disabled";
				};
				an7589_port11: port@10 {
					reg = <10>;
					label = "wan1";
					phy-mode = "usxgmii";
					sfp = <&sfp1>;
					port-handle = <&xsi_port10>;
					managed = "in-band-status";
					status = "disabled";
				};

				port@12 {
					reg = <12>;
					label = "cpu";
					ethernet = <&port0>;
					phy-mode = "internal";

					fixed-link {
						speed = <10000>;
						full-duplex;
						pause;
					};
				};
			};
		};
	};

	ipsec: ipsec@1fbfa000 {
		compatible = "airoha,airoha-ipsec";
		reg = <0x0 0x1fbfa000 0x0 0x268>;
		interrupts = <GIC_SPI 92 IRQ_TYPE_LEVEL_HIGH>; // IPSEC_INTR 20+72
	};

	pcm: pcm@1fbd0000 {
		compatible = "airoha,airoha-pcm";
		reg = <0x0 0x1fbd0000 0x0 0x4fff>;
		interrupts = <GIC_SPI 83 IRQ_TYPE_LEVEL_HIGH>;
	};

#if 1
		pciephy: phy@1fc0c000 {
			compatible = "airoha,an7589-pcie-phy";
			reg = <0x0 0x1fc0c000 0x0 0x800>,
				<0x0 0x1fc2c000 0x0 0x800>,
				<0x0 0x1fc10000 0x0 0xf00>,
				<0x0 0x1fc30000 0x0 0xf00>,
				<0x0 0x1fc50000 0x0 0xf00>;

			reg-names = "phyA-0", "phyA-1", "phyD-0", "phyD-1", "phyD-2";

			#phy-cells = <1>;

			pcie-serdes0{
				phy-index = <0>;
				lane-num = <2>;
			};
			pcie-serdes1{
				phy-index = <1>;
				lane-num = <2>;
			};
			pcie-serdes2{
				phy-index = <2>;
				lane-num = <1>;
			};
			pcie-serdes3{
				phy-index = <3>;
				lane-num = <1>;
			};
		};
#endif

#if 1
pcie0: pcie@1fc00000 {
			compatible = "airoha,an7589-pcie";
			device_type = "pci";
		linux,pci-domain = <0>;
			#address-cells = <3>;
			#size-cells = <2>;

			reg = <0x0 0x1fc00000 0x0 0x1670>;
			reg-names = "pcie-mac";

		phys = <&pciephy 0>,<&pciephy 1>;
		phy-names = "pcie-phy0";

			ranges = <0x02000000 0 0x20000000 0x0 0x20000000  0 0x4000000>;

		resets = <&scuclk AN7589_PCIE0_RST>,
				 <&scuclk AN7589_PCIE1_RST>,
				 <&scuclk AN7589_PCIE2_RST>;
		reset-names = "phy-lane0", "phy-lane1", "phy-lane2";

		mediatek,pbus-csr = <&pbus_csr 0x0 0x4>;

			interrupts = <GIC_SPI 95 IRQ_TYPE_LEVEL_HIGH>;
			bus-range = <0x00 0xff>;
			#interrupt-cells = <1>;
			interrupt-map-mask = <0 0 0 7>;
			interrupt-map = <0 0 0 1 &pcie_intc0 0>,
					<0 0 0 2 &pcie_intc0 1>,
					<0 0 0 3 &pcie_intc0 2>,
					<0 0 0 4 &pcie_intc0 3>;

			wifi-reset-gpios = <&an7589_pinctrl 70 GPIO_ACTIVE_LOW>;
			wifi-reset-msleep = <100>;
			wifi-deassert-msleep = <500>;

			status = "okay";

			pcie_intc0: interrupt-controller {
				interrupt-controller;
				#address-cells = <0>;
				#interrupt-cells = <1>;
			};

			pcie@0,0 {
				reg = <0x0000 0 0 0 0>;
				wifi@0,0 {
					reg = <0x0000 0 0 0 0>;
					airoha,npu = <&npu>;
				};
			};
		};
#endif

#if 1
pcie1: pcie@1fc20000 {
			compatible = "airoha,an7589-pcie";
			device_type = "pci";
		linux,pci-domain = <1>;
			#address-cells = <3>;
			#size-cells = <2>;

			reg = <0x0 0x1fc20000 0x0 0x1670>;
			reg-names = "pcie-mac";

		phys = <&pciephy 2>;
		phy-names = "pcie-phy1";

			ranges = <0x02000000 0 0x30000000 0x0 0x30000000  0 0x4000000>;

		resets = <&scuclk AN7589_PCIE0_RST>,
				 <&scuclk AN7589_PCIE1_RST>,
				 <&scuclk AN7589_PCIE2_RST>;
		reset-names = "phy-lane0", "phy-lane1", "phy-lane2";

		mediatek,pbus-csr = <&pbus_csr 0x8 0xc>;

			interrupts = <GIC_SPI 96 IRQ_TYPE_LEVEL_HIGH>;
			bus-range = <0x00 0xff>;
			#interrupt-cells = <1>;
			interrupt-map-mask = <0 0 0 7>;
			interrupt-map = <0 0 0 1 &pcie_intc1 0>,
					<0 0 0 2 &pcie_intc1 1>,
					<0 0 0 3 &pcie_intc1 2>,
					<0 0 0 4 &pcie_intc1 3>;

			status = "okay";

			pcie_intc1: interrupt-controller {
				interrupt-controller;
				#address-cells = <0>;
				#interrupt-cells = <1>;
			};

			pcie@1,0 {
				reg = <0x0000 0 0 0 0>;
				wifi@1,0 {
					reg = <0x0000 0 0 0 0>;
					airoha,npu = <&npu>;
				};
			};
		};
#endif

#if 1
pcie2: pcie@1fc40000 {
			compatible = "airoha,an7589-pcie";
			device_type = "pci";
		linux,pci-domain = <2>;
			#address-cells = <3>;
			#size-cells = <2>;

			reg = <0x0 0x1fc40000 0x0 0x1670>;
			reg-names = "pcie-mac";

		phys = <&pciephy 3>;
		phy-names = "pcie-phy2";

			ranges = <0x02000000 0 0x40000000 0x0 0x40000000  0 0x4000000>;

		resets = <&scuclk AN7589_PCIE0_RST>,
				 <&scuclk AN7589_PCIE1_RST>,
				 <&scuclk AN7589_PCIE2_RST>;
		reset-names = "phy-lane0", "phy-lane1", "phy-lane2";

		mediatek,pbus-csr = <&pbus_csr 0x10 0x14>;

			interrupts = <GIC_SPI 97 IRQ_TYPE_LEVEL_HIGH>;
			bus-range = <0x00 0xff>;
			#interrupt-cells = <1>;
			interrupt-map-mask = <0 0 0 7>;
			interrupt-map = <0 0 0 1 &pcie_intc2 0>,
					<0 0 0 2 &pcie_intc2 1>,
					<0 0 0 3 &pcie_intc2 2>,
					<0 0 0 4 &pcie_intc2 3>;

			status = "disabled";

			pcie_intc2: interrupt-controller {
				interrupt-controller;
				#address-cells = <0>;
				#interrupt-cells = <1>;
			};

			pcie@2,0 {
				reg = <0x0000 0 0 0 0>;
				wifi@2,0 {
					reg = <0x0000 0 0 0 0>;
					airoha,npu = <&npu>;
				};
			};
		};
#endif
#if 0
	ai_npu:	ai-npu@1fa3c000 {
		compatible = "airoha,ai-npu";
		memory-region = <&ai_npu_freeRTOS>, <&ai_npu_input>, <&ai_npu_model>, <&ai_npu_mbox>;
		memory-region-names = "firmware", "input", "model", "mbox";
		reg = <0x0 0x1fa3c000 0x0 0x3fff>;
		interrupts =
			<GIC_SPI 314 IRQ_TYPE_LEVEL_HIGH>,
			<GIC_SPI 315 IRQ_TYPE_LEVEL_HIGH>,
			<GIC_SPI 316 IRQ_TYPE_LEVEL_HIGH>,
			<GIC_SPI 317 IRQ_TYPE_LEVEL_HIGH>,
			<GIC_SPI 318 IRQ_TYPE_LEVEL_HIGH>,
			<GIC_SPI 319 IRQ_TYPE_LEVEL_HIGH>,
			<GIC_SPI 320 IRQ_TYPE_LEVEL_HIGH>,
			<GIC_SPI 321 IRQ_TYPE_LEVEL_HIGH>;
		airoha,scu = <&scuclk>;
	};
#endif
};
